AUTOSAR XML (schema 4-0-3)
package /ComponentTypes
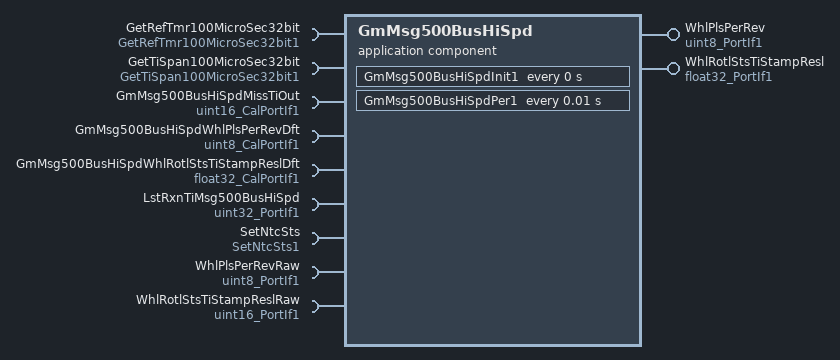
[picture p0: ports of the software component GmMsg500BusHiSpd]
  application sw component type GmMsg500BusHiSpd
    provide port WhlPlsPerRev: nonqueued-sender-com-spec{data-element=Val, init-value=1}, provided-interface=uint8_PortIf1
    provide port WhlRotlStsTiStampResl: nonqueued-sender-com-spec{data-element=Val, init-value=0.000000002}, provided-interface=float32_PortIf1
    9 x require port:
      GetRefTmr100MicroSec32bit: required-interface=GetRefTmr100MicroSec32bit1
      GetTiSpan100MicroSec32bit: required-interface=GetTiSpan100MicroSec32bit1
      GmMsg500BusHiSpdMissTiOut: parameter-require-com-spec{init-value=500, parameter=Val}, required-interface=uint16_CalPortIf1
      GmMsg500BusHiSpdWhlPlsPerRevDft: parameter-require-com-spec{init-value=48, parameter=Val}, required-interface=uint8_CalPortIf1
      GmMsg500BusHiSpdWhlRotlStsTiStampReslDft: parameter-require-com-spec{init-value=0.000004094, parameter=Val}, required-interface=float32_CalPortIf1
      LstRxnTiMsg500BusHiSpd: nonqueued-receiver-com-spec{data-element=Val, filter=data-filter-type=ALWAYS, init-value=0}, required-interface=uint32_PortIf1
      SetNtcSts: required-interface=SetNtcSts1
      WhlPlsPerRevRaw: nonqueued-receiver-com-spec{data-element=Val, filter=data-filter-type=ALWAYS, init-value=0}, required-interface=uint8_PortIf1
      WhlRotlStsTiStampReslRaw: nonqueued-receiver-com-spec{data-element=Val, filter=data-filter-type=ALWAYS, init-value=0}, required-interface=uint16_PortIf1
    behavior GmMsg500BusHiSpd_InternalBehavior: data-type-mapping=Nexteer
      ar-typed-per-instance-memorys:
        data GmMsg500BusHiSpdPrevRxnTi: sw-calibration-access=READ-ONLY, type=uint32
        data GmMsg500BusHiSpdPrevWhlPlsPerRev: sw-calibration-access=READ-ONLY, type=uint8
        data GmMsg500BusHiSpdPrevWhlRotlStsTiStampResl: sw-calibration-access=READ-ONLY, type=float32
      timing event GmMsg500BusHiSpd_InitEvent: start-on-event=GmMsg500BusHiSpdInit1, period=0
      timing event TMT_GM0C9HSPer1: start-on-event=GmMsg500BusHiSpdPer1, period=0.01
      runnable GmMsg500BusHiSpdInit1
      runnable GmMsg500BusHiSpdPer1
        data-receive-point-by-arguments:
          access REC_Msg0C9HSLstRxnTi_Val: accessed-variable=LstRxnTiMsg500BusHiSpd.Val
          access REC_WhlPlsPerRevRaw_Val: accessed-variable=WhlPlsPerRevRaw.Val
          access REC_WhlRotlStsTiStampReslRaw_Val: accessed-variable=WhlRotlStsTiStampReslRaw.Val
        data-send-points:
          access SEND_WhlPlsPerRev_Val: accessed-variable=WhlPlsPerRev.Val
          access SEND_WhlRotlStsTiStampResl_Val: accessed-variable=WhlRotlStsTiStampResl.Val
        sync call SC_GetRefTmr100MicroSec32bit_Oper: operation=GetRefTmr100MicroSec32bit.Oper, timeout=0
        sync call SC_GetTiSpan100MicroSec32bit_Oper: operation=GetTiSpan100MicroSec32bit.Oper, timeout=0
        sync call SC_SetNtcSts_Oper: operation=SetNtcSts.Oper, timeout=0
  swc implementation GmMsg500BusHiSpd_Implementation: behavior=GmMsg500BusHiSpd_InternalBehavior
    code-descriptors:
      code Default: artifact-descriptors=autosar-engineering-object={short-label=Default, category=SWSRC}
